# STM32MP157 register map
File version: 1.7
CPU: CM4 r0p1, little endian, no MPU, FPU, 4 interrupt priority bits
Registers are 32-bit, read-write, reset 0x0 unless marked. A register's access mark holds for its fields unless they carry their own. Offsets are from the block's base; [hi:lo] are bit positions; {n}, {i} and the like mark numbered series.

## DLYBQS
Base 0x58004000
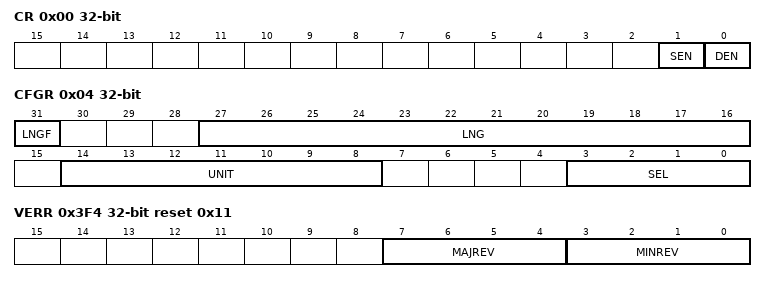
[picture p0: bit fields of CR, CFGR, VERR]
0x00 CR — DLYB control register
  [1] SEN, [0] DEN
0x04 CFGR — DLYB configuration register
  [31] LNGF ro, [27:16] LNG ro, [14:8] UNIT, [3:0] SEL
0x3F4 VERR ro reset 0x11 — DLYB IP version register
  [7:4] MAJREV, [3:0] MINREV
0x3F8 IPIDR ro reset 0x140051 — DLYB IP identification register
  [31:0] ID
0x3FC SIDR ro reset 0xA3C5DD01 — DLYB size ID register
  [31:0] SID

## DLYBSD1
Base 0x58006000
Same registers: DLYBSD3 0x48005000, DLYBSD2 0x58008000
Registers as DLYBQS; these are added or differ:
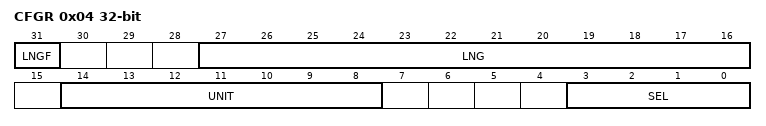
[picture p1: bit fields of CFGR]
0x04 CFGR access per field — DLYB configuration register
  [31] LNGF ro, [27:16] LNG ro, [14:8] UNIT rw, [3:0] SEL rw

## DMA1
Base 0x48000000
Same registers: DMA2 0x48001000
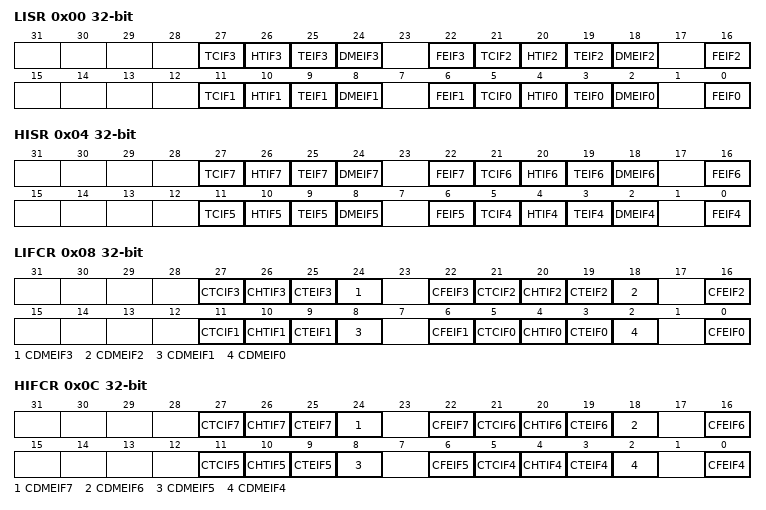
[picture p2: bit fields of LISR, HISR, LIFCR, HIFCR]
0x00 LISR ro — DMA low interrupt status register
  [27] TCIF3, [26] HTIF3, [25] TEIF3, [24] DMEIF3, [22] FEIF3, [21] TCIF2, [20] HTIF2, [19] TEIF2, [18] DMEIF2, [16] FEIF2, [11] TCIF1, [10] HTIF1, [9] TEIF1, [8] DMEIF1, [6] FEIF1, [5] TCIF0, [4] HTIF0, [3] TEIF0, [2] DMEIF0, [0] FEIF0
0x04 HISR ro — DMA high interrupt status register
  [27] TCIF7, [26] HTIF7, [25] TEIF7, [24] DMEIF7, [22] FEIF7, [21] TCIF6, [20] HTIF6, [19] TEIF6, [18] DMEIF6, [16] FEIF6, [11] TCIF5, [10] HTIF5, [9] TEIF5, [8] DMEIF5, [6] FEIF5, [5] TCIF4, [4] HTIF4, [3] TEIF4, [2] DMEIF4, [0] FEIF4
0x08 LIFCR wo — DMA low interrupt flag clear register
  [27] CTCIF3, [26] CHTIF3, [25] CTEIF3, [24] CDMEIF3, [22] CFEIF3, [21] CTCIF2, [20] CHTIF2, [19] CTEIF2, [18] CDMEIF2, [16] CFEIF2, [11] CTCIF1, [10] CHTIF1, [9] CTEIF1, [8] CDMEIF1, [6] CFEIF1, [5] CTCIF0, [4] CHTIF0, [3] CTEIF0, [2] CDMEIF0, [0] CFEIF0
0x0C HIFCR wo — DMA high interrupt flag clear register
  [27] CTCIF7, [26] CHTIF7, [25] CTEIF7, [24] CDMEIF7, [22] CFEIF7, [21] CTCIF6, [20] CHTIF6, [19] CTEIF6, [18] CDMEIF6, [16] CFEIF6, [11] CTCIF5, [10] CHTIF5, [9] CTEIF5, [8] CDMEIF5, [6] CFEIF5, [5] CTCIF4, [4] CHTIF4, [3] CTEIF4, [2] CDMEIF4, [0] CFEIF4
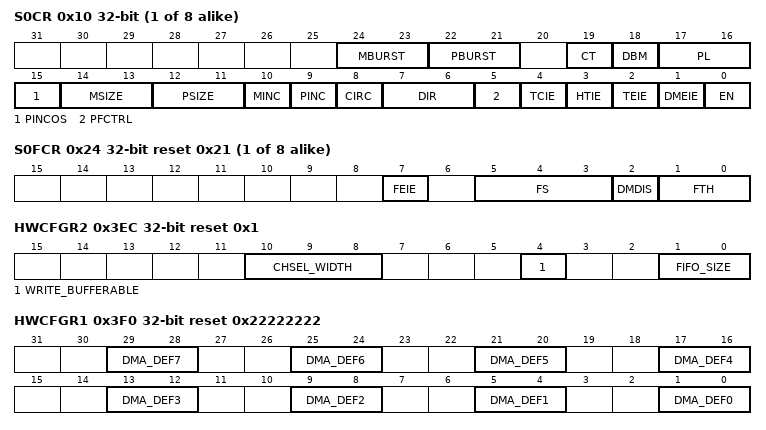
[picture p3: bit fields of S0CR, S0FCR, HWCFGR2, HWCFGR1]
{0x10+0x18*i} S{i}CR (i=0..7) — This register is used to configure the concerned stream.
  [24:23] MBURST, [22:21] PBURST, [19] CT, [18] DBM, [17:16] PL, [15] PINCOS, [14:13] MSIZE, [12:11] PSIZE, [10] MINC, [9] PINC, [8] CIRC, [7:6] DIR, [5] PFCTRL, [4] TCIE, [3] HTIE, [2] TEIE, [1] DMEIE, [0] EN
{0x14+0x18*i} S{i}NDTR (i=0..7) — DMA stream {i} number of data register
  [15:0] NDT
{0x18+0x18*i} S{i}PAR (i=0..7) — DMA stream {i} peripheral address register
  [31:0] PAR
{0x1C+0x18*i} S{i}M0AR (i=0..7) — DMA stream {i} memory 0 address register
  [31:0] M0A
{0x20+0x18*i} S{i}M1AR (i=0..7) — DMA stream {i} memory 1 address register
  [31:0] M1A
{0x24+0x18*i} S{i}FCR access per field reset 0x21 (i=0..7) — DMA stream {i} FIFO control register
  [7] FEIE rw, [5:3] FS ro, [2] DMDIS rw, [1:0] FTH rw
0x3EC HWCFGR2 ro reset 0x1 — DMA hardware configuration 2register
  [10:8] CHSEL_WIDTH, [4] WRITE_BUFFERABLE, [1:0] FIFO_SIZE
0x3F0 HWCFGR1 ro reset 0x22222222 — DMA hardware configuration 1 register
  [4n+1:4n] DMA_DEF{n} (n=0..7)
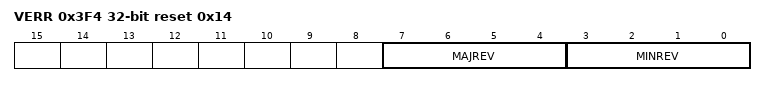
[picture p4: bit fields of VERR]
0x3F4 VERR ro reset 0x14 — This register identifies the version of the IP.
  [7:4] MAJREV, [3:0] MINREV
0x3F8 IPDR ro reset 0x100002 — DMA IP identification register
  [31:0] ID
0x3FC SIDR ro reset 0xA3C5DD01 — DMA size identification register
  [31:0] SID

## DMAMUX1
Base 0x48002000
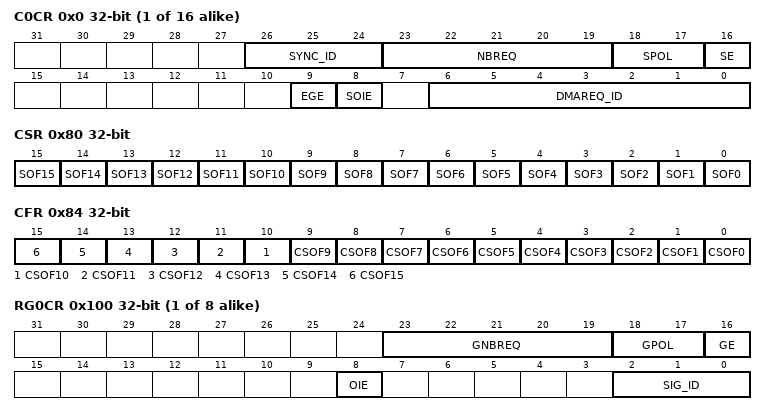
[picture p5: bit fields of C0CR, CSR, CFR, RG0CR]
{0x0+4i} C{i}CR (i=0..15) — DMAMUX request line multiplexer channel {i} configuration register
  [26:24] SYNC_ID, [23:19] NBREQ, [18:17] SPOL, [16] SE, [9] EGE, [8] SOIE, [6:0] DMAREQ_ID
0x80 CSR ro — DMAMUX request line multiplexer interrupt channel status register
  [n] SOF{n} (n=0..15)
0x84 CFR wo — DMAMUX request line multiplexer interrupt clear flag register
  [n] CSOF{n} (n=0..15)
{0x100+4i} RG{i}CR (i=0..7) — DMAMUX request generator channel {i} configuration register
  [23:19] GNBREQ, [18:17] GPOL, [16] GE, [8] OIE, [2:0] SIG_ID
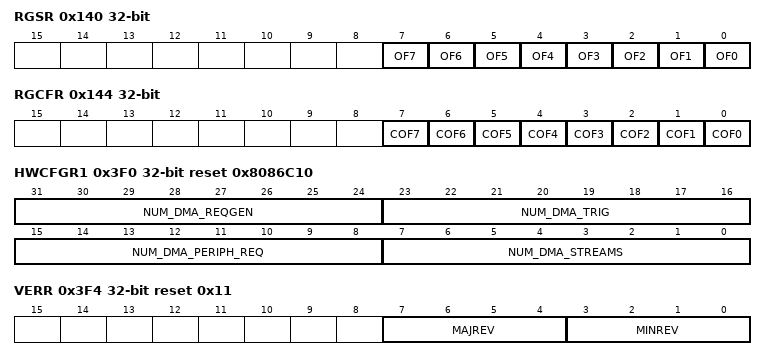
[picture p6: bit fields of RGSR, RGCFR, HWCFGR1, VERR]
0x140 RGSR ro — DMAMUX request generator interrupt status register
  [n] OF{n} (n=0..7)
0x144 RGCFR wo — DMAMUX request generator interrupt clear flag register
  [n] COF{n} (n=0..7)
0x3EC HWCFGR2 ro reset 0x8 — DMAMUX hardware configuration 2 register
  [7:0] NUM_DMA_EXT_REQ
0x3F0 HWCFGR1 ro reset 0x8086C10 — DMAMUX hardware configuration 1 register
  [31:24] NUM_DMA_REQGEN, [23:16] NUM_DMA_TRIG, [15:8] NUM_DMA_PERIPH_REQ, [7:0] NUM_DMA_STREAMS
0x3F4 VERR ro reset 0x11 — This register identifies the IP version.
  [7:4] MAJREV, [3:0] MINREV
0x3F8 IPIDR ro reset 0x100011 — This register identifies the IP.
  [31:0] ID
0x3FC SIDR ro reset 0xA3C5DD01 — DMAMUX size identification register
  [31:0] SID
